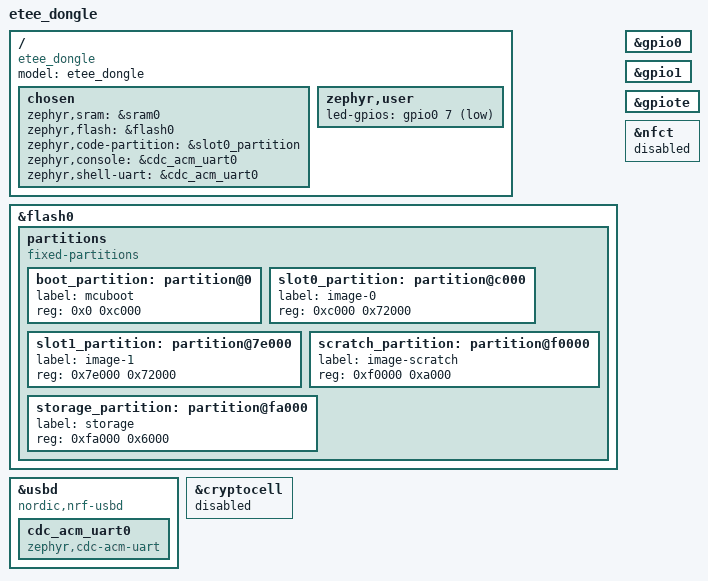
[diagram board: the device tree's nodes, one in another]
// Copyright (c) 2024 Nordic Semiconductor ASA
// SPDX-License-Identifier: Apache-2.0

/dts-v1/;
#include <nordic/nrf52840_qiaa.dtsi>

/ {
	model = "etee_dongle";
	compatible = "etee_dongle";

	chosen {
		zephyr,sram = &sram0;
		zephyr,flash = &flash0;
		zephyr,code-partition = &slot0_partition;
		zephyr,console = &cdc_acm_uart0;
		zephyr,shell-uart = &cdc_acm_uart0;
	};

	zephyr,user {
		led-gpios = <&gpio0 7 (GPIO_ACTIVE_LOW | GPIO_OPEN_DRAIN)>;
		// red 0.07, green 1.15, blue 1.09
	};
};

&flash0 {
	partitions {
		compatible = "fixed-partitions";
		#address-cells = <1>;
		#size-cells = <1>;

		boot_partition: partition@0 {
			label = "mcuboot";
			reg = <0x0 0xc000>;
		};
		slot0_partition: partition@c000 {
			label = "image-0";
			reg = <0xc000 0x72000>;
		};
		slot1_partition: partition@7e000 {
			label = "image-1";
			reg = <0x7e000 0x72000>;
		};
		scratch_partition: partition@f0000 {
			label = "image-scratch";
			reg = <0xf0000 0xa000>;
		};
		storage_partition: partition@fa000 {
			label = "storage";
			reg = <0xfa000 0x6000>;
		};
	};
};

&gpio0 {
	status = "okay";
};

&gpio1 {
	status = "okay";
};

&gpiote {
	status = "okay";
};

zephyr_udc0: &usbd {
	compatible = "nordic,nrf-usbd";
	status = "okay";
	cdc_acm_uart0: cdc_acm_uart0 {
		compatible = "zephyr,cdc-acm-uart";
	};
};

&cryptocell {
	status = "disabled";
};

&nfct {
	status = "disabled";
};
